# Port_9_10_5 register map
Vendor: Texas Instruments
Peripheral module from a debugger description file (folder msp430).
Registers are 8-bit, read-write, reset 0x0 unless marked. A register's access mark holds for its fields unless they carry their own. Offsets are as the file gives them; lines under a group give offsets from that group; [hi:lo] are bit positions; {n}, {i} and the like mark numbered series; 'fields as' and 'values as' point back to an identical list; <NAME> marks a mode.

## Port_9/10
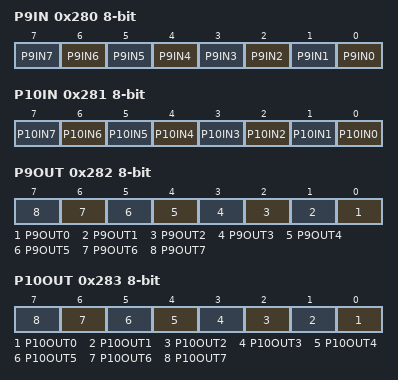
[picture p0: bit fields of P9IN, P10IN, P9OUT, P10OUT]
0x280 P9IN — Port 9 Input
  [n] P9IN{n} (n=0..7)
0x281 P10IN — Port 10 Input
  [n] P10IN{n} (n=0..7)
0x282 P9OUT — Port 9 Output
  [n] P9OUT{n} (n=0..7)
0x283 P10OUT — Port 10 Output
  [n] P10OUT{n} (n=0..7)
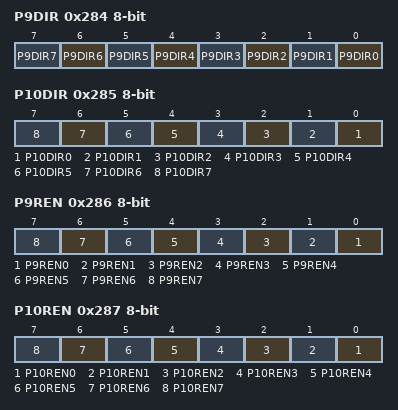
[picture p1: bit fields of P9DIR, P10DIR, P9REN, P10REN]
0x284 P9DIR — Port 9 Direction
  [n] P9DIR{n} (n=0..7)
0x285 P10DIR — Port 10 Direction
  [n] P10DIR{n} (n=0..7)
0x286 P9REN — Port 9 Resistor Enable
  [n] P9REN{n} (n=0..7)
0x287 P10REN — Port 10 Resistor Enable
  [n] P10REN{n} (n=0..7)
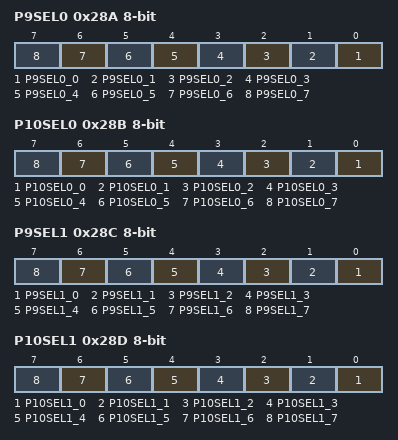
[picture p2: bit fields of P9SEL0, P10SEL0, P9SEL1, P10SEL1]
0x28A P9SEL0 — Port 9 Selection 0
  [n] P9SEL0_{n} (n=0..7)
0x28B P10SEL0 — Port 10 Selection 0
  [n] P10SEL0_{n} (n=0..7)
0x28C P9SEL1 — Port 9 Selection 1
  [n] P9SEL1_{n} (n=0..7)
0x28D P10SEL1 — Port 10 Selection 1
  [n] P10SEL1_{n} (n=0..7)
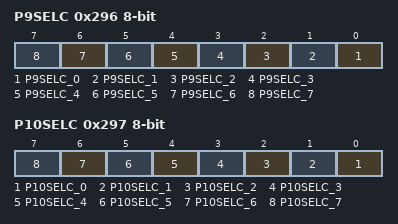
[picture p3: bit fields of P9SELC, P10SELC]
0x296 P9SELC — Port 9 Complement Selection
  [n] P9SELC_{n} (n=0..7)
0x297 P10SELC — Port 10 Complement Selection
  [n] P10SELC_{n} (n=0..7)
